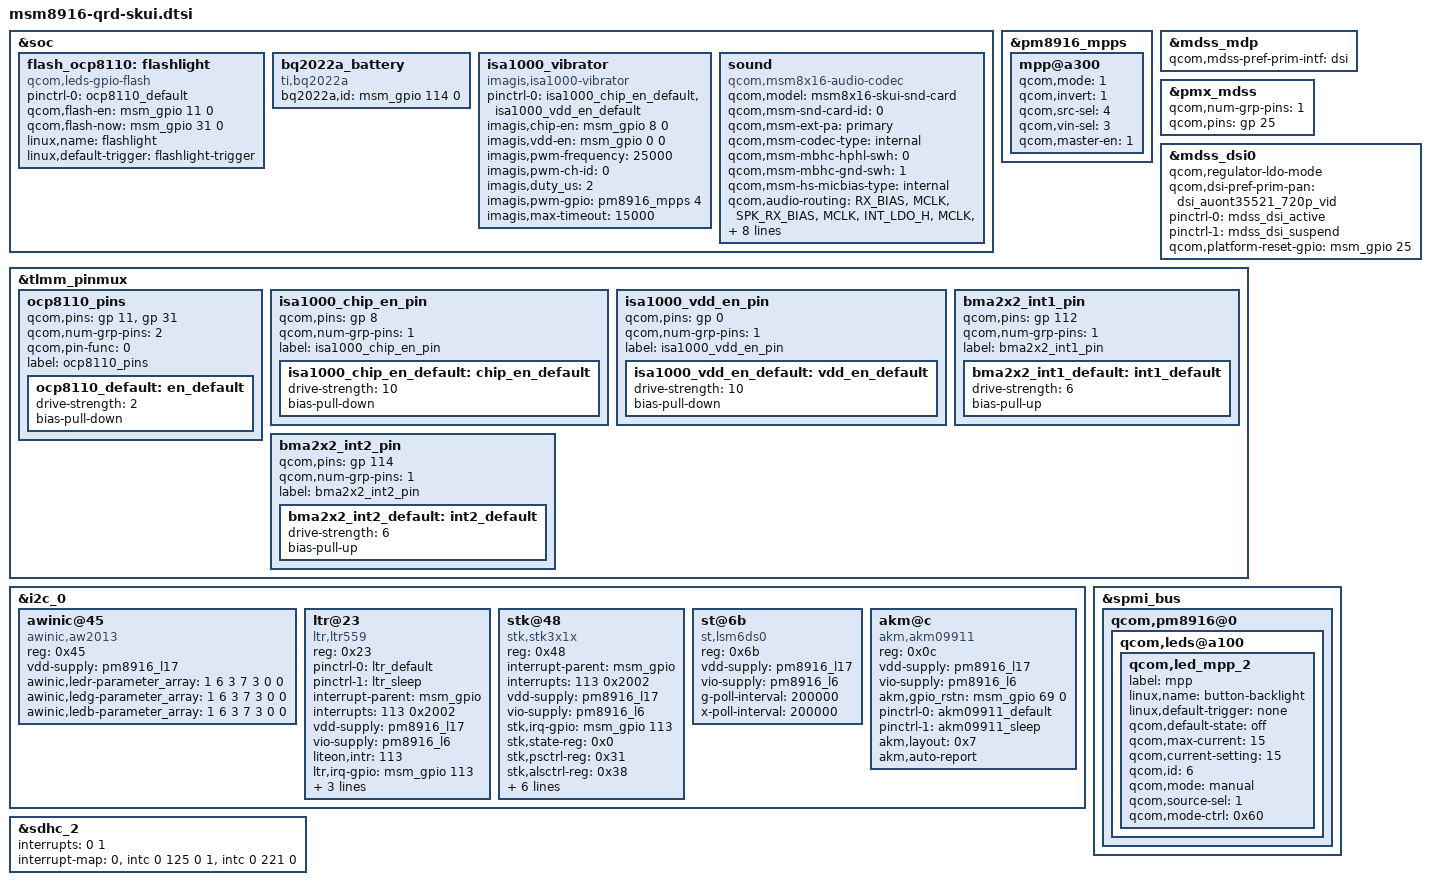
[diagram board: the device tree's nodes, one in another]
/* Copyright (c) 2014, The Linux Foundation. All rights reserved.
 * Copyright (C) 2016 XiaoMi, Inc.
 *
 * This program is free software; you can redistribute it and/or modify
 * it under the terms of the GNU General Public License version 2 and
 * only version 2 as published by the Free Software Foundation.
 *
 * This program is distributed in the hope that it will be useful,
 * but WITHOUT ANY WARRANTY; without even the implied warranty of
 * MERCHANTABILITY or FITNESS FOR A PARTICULAR PURPOSE.  See the
 * GNU General Public License for more details.
 */

#include "msm8916-qrd.dtsi"
#include "dsi-panel-auoNT35521-720p-video.dtsi"
#include "dsi-panel-boeNT35521-720p-video.dtsi"
#include "dsi-panel-ebbgNT35521-720p-video.dtsi"
#include "dsi-panel-lgNT35521-720p-video.dtsi"
#include "dsi-panel-sharpR69339-720p-video.dtsi"
#include "msm8916-camera-sensor-qrd-skui.dtsi"

&soc {
	flash_ocp8110:flashlight {
		compatible = "qcom,leds-gpio-flash";
		status = "okay";
		pinctrl-names = "ocp8110_default";
		pinctrl-0 = <&ocp8110_default>;
		qcom,flash-en = <&msm_gpio 11 0>;
		qcom,flash-now = <&msm_gpio 31 0>;
		linux,name = "flashlight";
		linux,default-trigger = "flashlight-trigger";
	};


	bq2022a_battery {
		compatible = "ti,bq2022a";
		status = "okay";
		bq2022a,id = <&msm_gpio 114 0>;
	};

	isa1000_vibrator {
		compatible = "imagis,isa1000-vibrator";
		status = "okay";
		pinctrl-names = "isa1000_default";
		pinctrl-0 = <&isa1000_chip_en_default &isa1000_vdd_en_default>;
		imagis,chip-en = <&msm_gpio 8 0>;
		imagis,vdd-en = <&msm_gpio 0 0>;
		imagis,pwm-frequency = <25000>;
		imagis,pwm-ch-id = <0>;
		imagis,duty_us = <2>;
		imagis,pwm-gpio = <&pm8916_mpps 4 0>;
		imagis,max-timeout = <15000>;
	};

	sound {
		compatible = "qcom,msm8x16-audio-codec";
		qcom,model = "msm8x16-skui-snd-card";
		qcom,msm-snd-card-id = <0>;
		qcom,msm-ext-pa = "primary";
		qcom,msm-codec-type = "internal";
		qcom,msm-mbhc-hphl-swh = <0>;
		qcom,msm-mbhc-gnd-swh = <1>;
		qcom,msm-hs-micbias-type = "internal";
		qcom,audio-routing =
			"RX_BIAS", "MCLK",
			"SPK_RX_BIAS", "MCLK",
			"INT_LDO_H", "MCLK",
			"MIC BIAS Internal1", "Handset Mic",
			"MIC BIAS Internal2", "Headset Mic",
			"MIC BIAS Internal3", "Secondary Mic",
			"AMIC1", "MIC BIAS Internal1",
			"AMIC2", "MIC BIAS Internal2",
			"AMIC3", "MIC BIAS Internal3";
		pinctrl-names = "cdc_lines_act",
				"cdc_lines_sus";
		pinctrl-0 = <&cdc_pdm_lines_act>;
		pinctrl-1 = <&cdc_pdm_lines_sus>;
	};
};

&pm8916_mpps {
	mpp@a300 { /* MPP 4 */
		/* Backlight PWM */
		qcom,mode = <1>;		/* Digital output */
		qcom,invert = <1>;		/* Disable Invert */
		qcom,src-sel = <4>;		/* DTEST1 */
		qcom,vin-sel = <3>;		/* VPH_PWR */
		qcom,master-en = <1>;		/* Enable MPP */
	};
};

&mdss_mdp {
	qcom,mdss-pref-prim-intf = "dsi";
};

&pmx_mdss {
	qcom,num-grp-pins = <1>;
	qcom,pins = <&gp 25>;
};

&mdss_dsi0 {
	qcom,regulator-ldo-mode;
	qcom,dsi-pref-prim-pan = <&dsi_auont35521_720p_vid>;
	pinctrl-names = "mdss_default", "mdss_sleep";
	pinctrl-0 = <&mdss_dsi_active>;
	pinctrl-1 = <&mdss_dsi_suspend>;

	qcom,platform-reset-gpio = <&msm_gpio 25 0>;
};
&tlmm_pinmux {
	ocp8110_pins {
		qcom,pins = <&gp 11>, <&gp 31>;
		qcom,num-grp-pins = <2>;
		qcom,pin-func = <0>;
		label = "ocp8110_pins";
		ocp8110_default: en_default {
			  drive-strength = <2>;
			  bias-pull-down;
		};
	};
	isa1000_chip_en_pin {
		qcom,pins = <&gp 8>;
		qcom,num-grp-pins = <1>;
		label = "isa1000_chip_en_pin";
		isa1000_chip_en_default: chip_en_default {
			drive-strength = <10>;
			bias-pull-down;
		};
	};

	isa1000_vdd_en_pin {
		qcom,pins = <&gp 0>;
		qcom,num-grp-pins = <1>;
		label = "isa1000_vdd_en_pin";
		isa1000_vdd_en_default: vdd_en_default {
			  drive-strength = <10>;
			  bias-pull-down;
		};
	};

	bma2x2_int1_pin {
		qcom,pins = <&gp 112>;
		qcom,num-grp-pins = <1>;
		label = "bma2x2_int1_pin";
		bma2x2_int1_default: int1_default {
			  drive-strength = <6>;
			  bias-pull-up;
		};
	};

	bma2x2_int2_pin {
		qcom,pins = <&gp 114>;
		qcom,num-grp-pins = <1>;
		label = "bma2x2_int2_pin";
		bma2x2_int2_default: int2_default {
			  drive-strength = <6>;
			  bias-pull-up;
		};
	};
};

&i2c_0 { /* BLSP1 QUP2 */
	awinic@45 { /* Breath Light-Driven */

		compatible = "awinic,aw2013";
		reg = <0x45>;
		vdd-supply = <&pm8916_l17>;
		awinic,ledr-parameter_array = <1 6 3 7 3 0 0>;
		awinic,ledg-parameter_array = <1 6 3 7 3 0 0>;
		awinic,ledb-parameter_array = <1 6 3 7 3 0 0>;
	};

	ltr@23 {
		compatible = "ltr,ltr559";
		reg = <0x23>;
		pinctrl-names = "default","sleep";
		pinctrl-0 = <&ltr_default>;
		pinctrl-1 = <&ltr_sleep>;
		interrupt-parent = <&msm_gpio>;
		interrupts = <113 0x2002>;
		vdd-supply = <&pm8916_l17>;
		vio-supply = <&pm8916_l6>;
		liteon,intr = <113>;
		ltr,irq-gpio = <&msm_gpio 113 0x2002>;
		ltr,ps-threshold = <390>;
		ltr,ps-hysteresis-threshold = <310>;
		ltr,als-polling-time = <200>;
	};

	stk@48 { /* Ambient light and proximity sensor */
		compatible = "stk,stk3x1x";
		reg = <0x48>;
		interrupt-parent = <&msm_gpio>;
		interrupts = <113 0x2002>;
		vdd-supply = <&pm8916_l17>;
		vio-supply = <&pm8916_l6>;
		stk,irq-gpio = <&msm_gpio 113 0x2002>;
		stk,state-reg = <0x0>;
		stk,psctrl-reg = <0x31>;
		stk,alsctrl-reg = <0x38>;
		stk,ledctrl-reg = <0xFF>;
		stk,wait-reg = <0x07>;
		stk,ps-thdh = <1700>;
		stk,ps-thdl = <1500>;
		stk,transmittance = <500>;
		stk,use-fir;
	};

	st@6b { /* Accelerometer & Gyroscope sensors */
		compatible = "st,lsm6ds0";
		reg = <0x6b>;
		vdd-supply = <&pm8916_l17>;
		vio-supply = <&pm8916_l6>;
		g-poll-interval = <200000>;
		x-poll-interval = <200000>;
	};

	akm@c { /* Compass sensor */
		compatible = "akm,akm09911";
		reg = <0x0c>;
		vdd-supply = <&pm8916_l17>;
		vio-supply = <&pm8916_l6>;
		akm,gpio_rstn = <&msm_gpio 69 0>;
		pinctrl-names = "default","sleep";
		pinctrl-0 = <&akm09911_default>;
		pinctrl-1 = <&akm09911_sleep>;
		akm,layout = <0x7>;
		akm,auto-report;
	};

};
&spmi_bus {
	qcom,pm8916@0 {
		qcom,leds@a100 {
			status = "okay";
			qcom,led_mpp_2 {
			label = "mpp";
			linux,name = "button-backlight";
			linux,default-trigger = "none";
			qcom,default-state = "off";
			qcom,max-current = <15>;
			qcom,current-setting = <15>;
			qcom,id = <6>;
			qcom,mode = "manual";
			qcom,source-sel = <1>;
			qcom,mode-ctrl = <0x60>;
			};
		};
	};
};



&sdhc_2 {
	interrupts = <0 1>;
	interrupt-map = <0 &intc 0 125 0
		1 &intc 0 221 0>;
	interrupt-names = "hc_irq", "pwr_irq";
	/delete-property/ cd-gpios;
};

